# mcr_me55 register map
Registers are access not given, no defined reset value unless marked. A register's access mark holds for its fields unless they carry their own. Offsets are from the block's base; lines under a group give offsets from that group; [hi:lo] are bit positions; {n}, {i} and the like mark numbered series; 'fields as' and 'values as' point back to an identical list; <NAME> marks a mode.

## Memory map
0x40006C00 MCR size 0x400 — Misc Control.

## MCR — Misc Control.
Base 0x40006C00
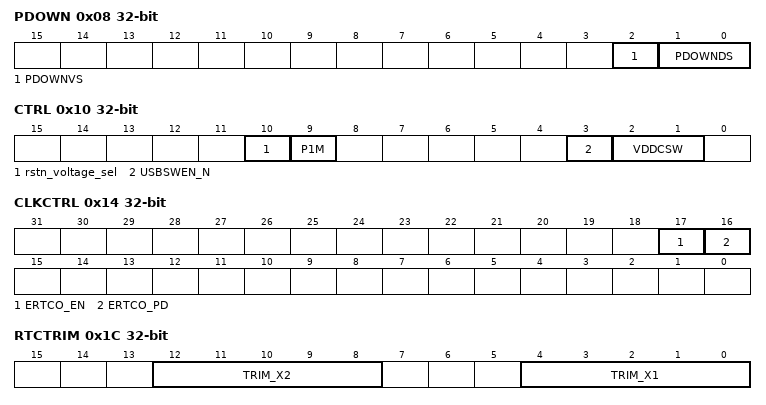
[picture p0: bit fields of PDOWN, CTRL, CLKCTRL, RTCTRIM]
0x08 PDOWN — PDOWN Drive Strength
  [2] PDOWNVS — PDOWN Voltage Select
  [1:0] PDOWNDS — PDOWN Drive Strength
0x10 CTRL — Misc Power State Control Register
  [10] rstn_voltage_sel — Error! Description not Found!
  [9] P1M — Enable the Reset Pad Pull Up Resistors
    0=1m (1MOhm Pullup); 1=25k (25kOhm Pullup.)
  [3] USBSWEN_N — USB Switch Control
    1=off (USB SW off in LP modes); 0=on (USB SW On)
  [2:1] VDDCSW — Controls switching of VCORE
0x14 CLKCTRL — Clock Control Register.
  [17] ERTCO_EN — 32kHz Crystal Oscillator Enable.
  [16] ERTCO_PD — 32kHz Crystal Oscillator Power Down.
0x18 RST — Reset Register.
  [0] RTC — Real Time Cock Reset.
0x1C RTCTRIM
  [12:8] TRIM_X2 — RTC TRIM X2
  [4:0] TRIM_X1 — RTC Trim X1
0x60 LDOCTRL — LDO Control Register.
  [0] 0P9V_EN — LDO 0.9V Enable.
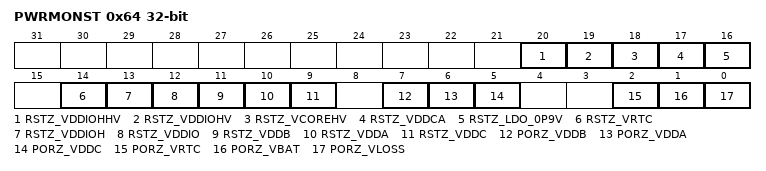
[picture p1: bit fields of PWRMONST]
0x64 PWRMONST — Power Monitor Statuses Register.
  [20] RSTZ_VDDIOHHV — Non-sticky bit indicating high voltage reset condition on VDDIOH supply.
  [19] RSTZ_VDDIOHV — Non-sticky bit indicating high voltage reset condition on VDDIO supply.
  [18] RSTZ_VCOREHV — Non-sticky bit indicating high voltage reset condition on VCORE supply.
  [17] RSTZ_VDDCA — Non-sticky bit indicating reset condition on VCORE in Analog supply.
  [16] RSTZ_LDO_0P9V — Non-sticky bit indicating reset condition on 0.9V USB supply.
  [14] RSTZ_VRTC — Sticky bit indicating reset condition on RTC.
  [13] RSTZ_VDDIOH — Sticky bit indicating reset condition on VDDIOH.
  [12] RSTZ_VDDIO — Sticky bit indicating reset condition on VDDIO.
  [11] RSTZ_VDDB — Sticky bit indicating reset condition on VDDB.
  [10] RSTZ_VDDA — Sticky bit indicating reset condition on VDDA.
  [9] RSTZ_VDDC — Sticky bit indicating reset condition on VCORE.
  [7] PORZ_VDDB — Sticky bit indicating power on status of VDDB.
  [6] PORZ_VDDA — Sticky bit indicating power on status of VDDA.
  [5] PORZ_VDDC — Sticky bit indicating power on status of VCORE.
  [2] PORZ_VRTC — Sticky bit indicating power on status of the RTC.
  [1] PORZ_VBAT — Sticky bit indicating power on status of the battery.
  [0] PORZ_VLOSS — Sticky bit indicating power on status of core power domains.
